# M2Sxxx register map
Vendor: Microsemi; Series: SmartFusion2; File version: 2.0.32
CPU: CM3 r2p1, little endian, MPU, no FPU, 4 interrupt priority bits
Registers are 32-bit, read-write, no defined reset value unless marked. A register's access mark holds for its fields unless they carry their own. Offsets are from the block's base; [hi:lo] are bit positions; {n}, {i} and the like mark numbered series.

## I2C0 — No description provided for this peripheral
Base 0x40002000
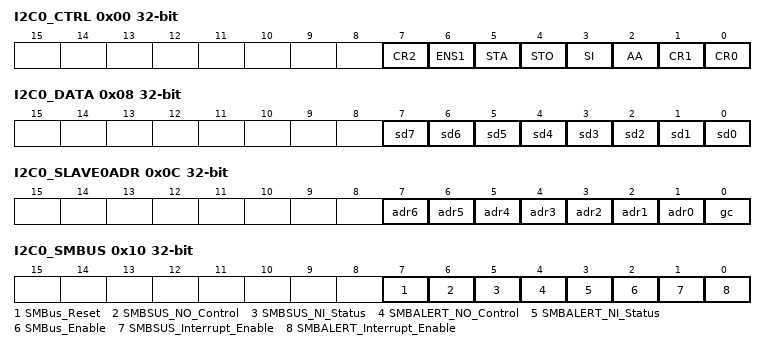
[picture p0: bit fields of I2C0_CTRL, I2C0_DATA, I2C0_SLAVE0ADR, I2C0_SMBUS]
0x00 I2C0_CTRL — No description provided for this register
  [7] CR2 — No description provided for this field
  [6] ENS1 — No description provided for this field
  [5] STA — No description provided for this field
  [4] STO — No description provided for this field
  [3] SI — No description provided for this field
  [2] AA — No description provided for this field
  [1] CR1 — No description provided for this field
  [0] CR0 — No description provided for this field
0x04 I2C0_STATUS — No description provided for this register
  [7:0] Status_Register ro — No description provided for this field
0x08 I2C0_DATA — No description provided for this register
  [n] sd{n} (n=0..7) — No description provided for this field
0x0C I2C0_SLAVE0ADR — No description provided for this register
  [n+1] adr{n} (n=0..6) — No description provided for this field
  [0] gc — No description provided for this field
0x10 I2C0_SMBUS — No description provided for this register
  [7] SMBus_Reset — No description provided for this field
  [6] SMBSUS_NO_Control — No description provided for this field
  [5] SMBSUS_NI_Status — No description provided for this field
  [4] SMBALERT_NO_Control — No description provided for this field
  [3] SMBALERT_NI_Status — No description provided for this field
  [2] SMBus_Enable — No description provided for this field
  [1] SMBSUS_Interrupt_Enable — No description provided for this field
  [0] SMBALERT_Interrupt_Enable — No description provided for this field
0x14 I2C0_FREQ — No description provided for this register
  [7:0] Frequency — No description provided for this field
0x18 I2C0_GLITCHREG — No description provided for this register
  [7:0] GlitchReg_Num — No description provided for this field
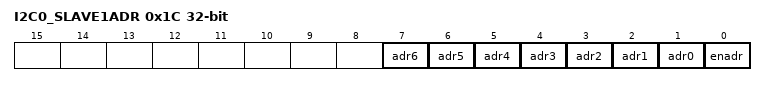
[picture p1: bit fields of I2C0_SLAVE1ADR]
0x1C I2C0_SLAVE1ADR — No description provided for this register
  [n+1] adr{n} (n=0..6) — No description provided for this field
  [0] enadr — No description provided for this field

## I2C1 — No description provided for this peripheral
Base 0x40012000
Registers as I2C0 (with I2C0 read as I2C1).

## HPDMA — No description provided for this peripheral
Base 0x40014000
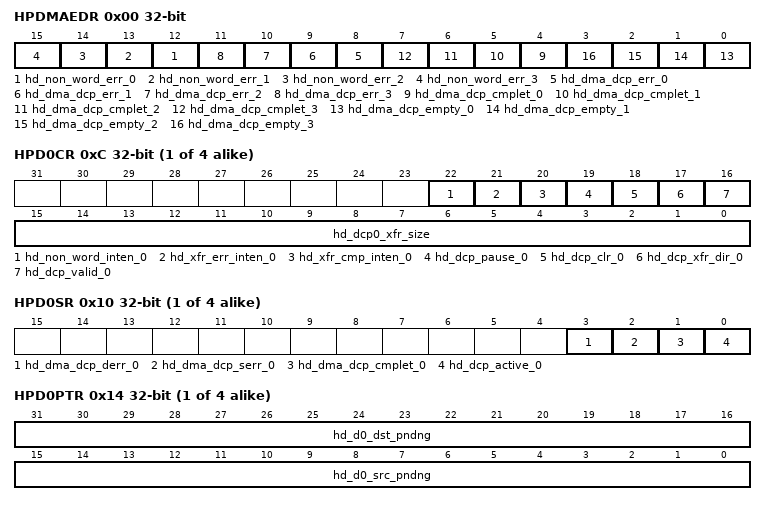
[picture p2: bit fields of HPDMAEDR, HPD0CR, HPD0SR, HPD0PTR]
0x00 HPDMAEDR — No description provided for this register
  [n+12] hd_non_word_err_{n} ro (n=0..3) — No description provided for this field
  [n+8] hd_dma_dcp_err_{n} ro (n=0..3) — No description provided for this field
  [n+4] hd_dma_dcp_cmplet_{n} ro (n=0..3) — No description provided for this field
  [n] hd_dma_dcp_empty_{n} ro (n=0..3) — No description provided for this field
{0x4+0x14*i} HPD{i}SAR (i=0..3) — No description provided for this register
  [31:0] hd_dcp{i}_src_adrs — No description provided for this field
{0x8+0x14*i} HPD{i}DAR (i=0..3) — No description provided for this register
  [31:0] hd_dcp{i}_dst_adrs — No description provided for this field
{0xC+0x14*i} HPD{i}CR (i=0..3) — No description provided for this register
  [22] hd_non_word_inten_{i} — No description provided for this field
  [21] hd_xfr_err_inten_{i} — No description provided for this field
  [20] hd_xfr_cmp_inten_{i} — No description provided for this field
  [19] hd_dcp_pause_{i} — No description provided for this field
  [18] hd_dcp_clr_{i} — No description provided for this field
  [17] hd_dcp_xfr_dir_{i} — No description provided for this field
  [16] hd_dcp_valid_{i} — No description provided for this field
  [15:0] hd_dcp{i}_xfr_size — No description provided for this field
{0x10+0x14*i} HPD{i}SR (i=0..3) — No description provided for this register
  [3] hd_dma_dcp_derr_{i} ro — No description provided for this field
  [2] hd_dma_dcp_serr_{i} ro — No description provided for this field
  [1] hd_dma_dcp_cmplet_{i} ro — No description provided for this field
  [0] hd_dcp_active_{i} ro — No description provided for this field
{0x14+0x14*i} HPD{i}PTR (i=0..3) — No description provided for this register
  [31:16] hd_d{i}_dst_pndng ro — No description provided for this field
  [15:0] hd_d{i}_src_pndng ro — No description provided for this field
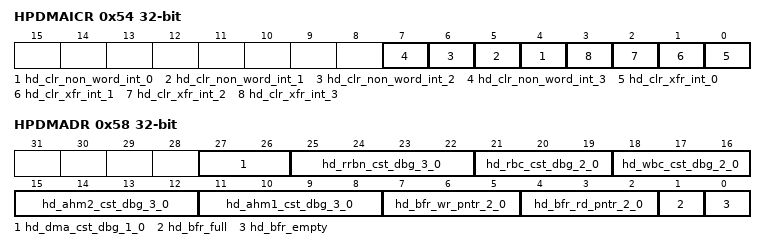
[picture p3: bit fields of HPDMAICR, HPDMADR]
0x54 HPDMAICR — No description provided for this register
  [n+4] hd_clr_non_word_int_{n} wo (n=0..3) — No description provided for this field
  [n] hd_clr_xfr_int_{n} wo (n=0..3) — No description provided for this field
0x58 HPDMADR — No description provided for this register
  [27:26] hd_dma_cst_dbg_1_0 ro — No description provided for this field
  [25:22] hd_rrbn_cst_dbg_3_0 ro — No description provided for this field
  [21:19] hd_rbc_cst_dbg_2_0 ro — No description provided for this field
  [18:16] hd_wbc_cst_dbg_2_0 ro — No description provided for this field
  [15:12] hd_ahm2_cst_dbg_3_0 ro — No description provided for this field
  [11:8] hd_ahm1_cst_dbg_3_0 ro — No description provided for this field
  [7:5] hd_bfr_wr_pntr_2_0 ro — No description provided for this field
  [4:2] hd_bfr_rd_pntr_2_0 ro — No description provided for this field
  [1] hd_bfr_full ro — No description provided for this field
  [0] hd_bfr_empty ro — No description provided for this field
